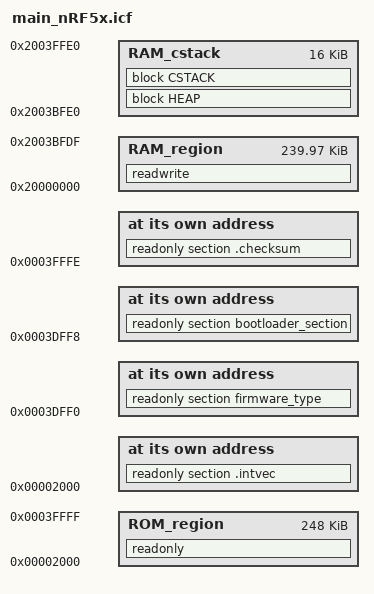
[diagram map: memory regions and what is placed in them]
/*###ICF### Section handled by ICF editor, don't touch! ****/
/*-Editor annotation file-*/
/* IcfEditorFile="$TOOLKIT_DIR$\config\ide\IcfEditor\cortex_v1_0.xml" */
/*-Specials-*/
define symbol __ICFEDIT_intvec_start__ = 0x2000;
define symbol __CHECKSUM__             = 0x3FFFE;
/*-Memory Regions-*/
define symbol __ICFEDIT_region_ROM_start__ = 0x2000;
define symbol __ICFEDIT_region_ROM_end__   = 0x3ffff;
define symbol __BOOTLOADER_IMG             = 0x3DFF8;
define symbol __FIRMWARE_TYPE              = 0x3DFF0;

define symbol __ICFEDIT_region_RAM_start__ = 0x20000000;
define symbol __ICFEDIT_region_RAM_end__   = 0x2003BFDF;

define symbol __ICFEDIT_stack_RAM_start__ = 0x2003BFE0;
define symbol __ICFEDIT_stack_RAM_end__   = 0x2003FFE0;

/*-Sizes-*/
define symbol __ICFEDIT_size_cstack__ = 0x2000;
define symbol __ICFEDIT_size_heap__   = 0x2000;
/**** End of ICF editor section. ###ICF###*/

define memory mem with size = 4G;
define region ROM_region   = mem:[from __ICFEDIT_region_ROM_start__   to __ICFEDIT_region_ROM_end__];
define region RAM_region   = mem:[from __ICFEDIT_region_RAM_start__   to __ICFEDIT_region_RAM_end__];
define region RAM_cstack   = mem:[from __ICFEDIT_stack_RAM_start__   to __ICFEDIT_stack_RAM_end__];

define block CSTACK    with alignment = 8, size = __ICFEDIT_size_cstack__   { };
define block HEAP      with alignment = 8, size = __ICFEDIT_size_heap__     { };

initialize by copy { readwrite };
do not initialize  { section .noinit };

keep { section .intvec };
place at address mem: __ICFEDIT_intvec_start__ { readonly section .intvec };
place at address mem: __CHECKSUM__   { readonly section .checksum };
place at address mem: __FIRMWARE_TYPE  { readonly section firmware_type };
place at address mem: __BOOTLOADER_IMG { readonly section bootloader_section }; 
place in ROM_region   { readonly };
place in RAM_region   { readwrite };
place in RAM_cstack   { block HEAP,
                        block CSTACK };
